# WKUP_I2C0_CFG register map
Vendor: Texas Instruments
Peripheral module from a debugger description file (folder J722S).
Registers are 32-bit, read-write, reset 0x0 unless marked. A register's access mark holds for its fields unless they carry their own. Offsets are as the file gives them; lines under a group give offsets from that group; [hi:lo] are bit positions; {n}, {i} and the like mark numbered series; 'fields as' and 'values as' point back to an identical list; <NAME> marks a mode.

## WKUP_I2C0_CFG
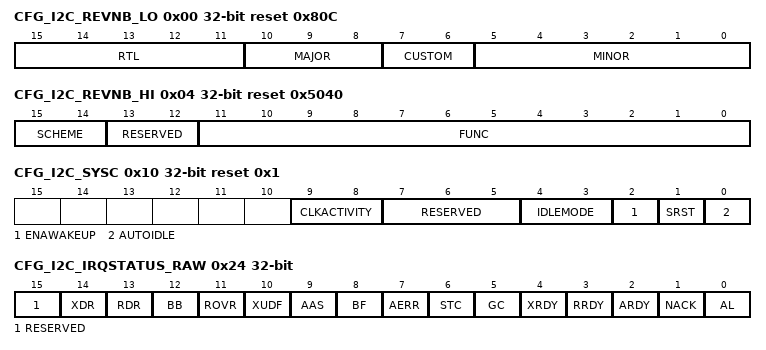
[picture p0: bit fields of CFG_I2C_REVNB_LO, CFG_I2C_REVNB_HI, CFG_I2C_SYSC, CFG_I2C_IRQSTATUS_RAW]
0x00 CFG_I2C_REVNB_LO ro reset 0x80C — Revision Number register (Low)
  [15:11] RTL — RTL version This field changes on bug fix, and resets to
  [10:8] MAJOR — Major Revision This field changes when there is a major feature change This field does not change due to bug fix, or minor feature change
  [7:6] CUSTOM — Indicates a special version for a particular device Consequence of use may avoid use of standard Chip Support Library [CSL] / Drivers 0 if non-custom
  [5:0] MINOR — Minor Revision This field changes when features are scaled up or down This field does not change due to bug fix, or major feature change
0x04 CFG_I2C_REVNB_HI ro reset 0x5040 — Revision Number register (High)
  [15:14] SCHEME — Used to distinguish between old Scheme and current Spare bit to encode future schemes
  [13:12] RESERVED — Reads return 0x1
  [11:0] FUNC — Function: Indicates a software compatible module family
0x10 CFG_I2C_SYSC access not given reset 0x1 — System Configuration register
  [9:8] CLKACTIVITY rw — Clock Activity selection bits
  [7:5] RESERVED — Reads return 0 (access N/A)
  [4:3] IDLEMODE rw — Idle Mode selection bits
  [2] ENAWAKEUP rw — Enable Wakeup control bit
  [1] SRST rw — SoftReset bit
  [0] AUTOIDLE rw — Autoidle bit
0x20 CFG_I2C_EOI wo — End Of Interrupt number specification
  [0] LINE_NUMBER — Software End Of Interrupt [EOI] control Write number of interrupt output
0x24 CFG_I2C_IRQSTATUS_RAW access not given — Per-event raw interrupt status vector
  [15] RESERVED — Write 0s for future compatibility Read returns 0 (access N/A)
  [14] XDR rw — Transmit draining IRQ status
  [13] RDR rw — Receive draining IRQ status
  [12] BB ro — Bus busy statusWriting into this bit has no effect
  [11] ROVR rw — Receive overrun statusWriting into this bit has no effect
  [10] XUDF rw — Transmit underflow statusWriting into this bit has no effect
  [9] AAS rw — Address recognized as target IRQ status
  [8] BF rw — Bus Free IRQ status
  [7] AERR rw — Access Error IRQ status
  [6] STC rw — Start Condition IRQ status
  [5] GC — General call IRQ status Set to '1' by core when General call address detected and interrupt signaled to MPUSS Write '1' to clear (access R/W1C)
  [4] XRDY — Transmit data ready IRQ status Set to '1' by core when transmitter and when new data is requested When set to '1' by core, an interrupt is signaled to MPUSS Write '1' to clear (access R/W1C)
  [3] RRDY — Receive data ready IRQ status Set to '1' by core when receiver mode, a new data is able to be read When set to '1' by core, an interrupt is signaled to MPUSS Write '1' to clear (access R/W1C)
  [2] ARDY — Register access ready IRQ status When set to '1' it indicates that previous access has been performed and registers are ready to be accessed again An interrupt is signaled to MPUSS Write '1' to clear (access R/W1C)
  [1] NACK — No acknowledgement IRQ status Bit is set when No Acknowledge has been received, an interrupt is signaled to MPUSS Write '1' to clear this bit (access R/W1C)
  [0] AL rw — Arbitration lost IRQ status This bit is automatically set by the hardware when it loses the Arbitration in controller transmit mode, an interrupt is signaled to MPUSS During reads, it always returns 0
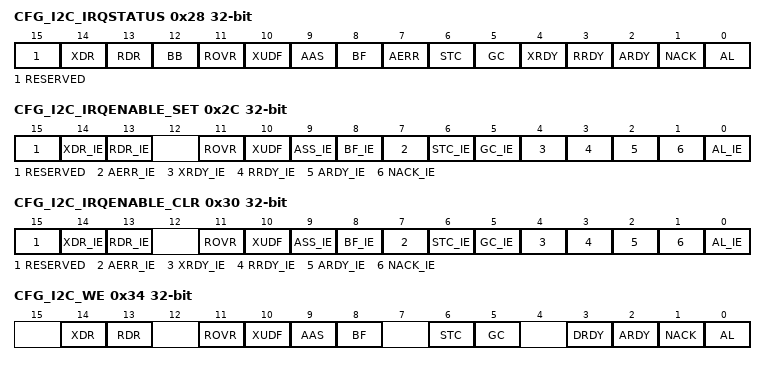
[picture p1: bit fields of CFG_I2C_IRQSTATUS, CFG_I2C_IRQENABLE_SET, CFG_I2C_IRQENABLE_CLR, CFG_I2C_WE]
0x28 CFG_I2C_IRQSTATUS access not given — Per-event enabled interrupt status vector
  [15] RESERVED — Write 0s for future compatibility Read returns 0 (access N/A)
  [14] XDR rw — Transmit draining IRQ enabled status
  [13] RDR rw — Receive draining IRQ enabled status
  [12] BB ro — Bus busy enabled statusWriting into this bit has no effect
  [11] ROVR rw — Receive overrun enabled statusWriting into this bit has no effect
  [10] XUDF rw — Transmit underflow enabled statusWriting into this bit has no effect
  [9] AAS rw — Address recognized as target IRQ enabled status
  [8] BF rw — Bus Free IRQ enabled status
  [7] AERR rw — Access Error IRQ enabled status
  [6] STC rw — Start Condition IRQ enabled status
  [5] GC rw — General call IRQ enabled status Set to '1' by core when General call address detected and interrupt signaled to MPUSS Write '1' to clear
  [4] XRDY rw — Transmit data ready IRQ enabled status Set to '1' by core when transmitter and when new data is requested When set to '1' by core, an interrupt is signaled to MPUSS Write '1' to clear
  [3] RRDY rw — Receive data ready IRQ enabled status Set to '1' by core when receiver mode, a new data is able to be read When set to '1' by core, an interrupt is signaled to MPUSS Write '1' to clear
  [2] ARDY rw — Register access ready IRQ enabled status When set to '1' it indicates that previous access has been performed and registers are ready to be accessed again An interrupt is signaled to MPUSS Write '1' to clear
  [1] NACK rw — No acknowledgement IRQ enabled status Bit is set when No Acknowledge has been received, an interrupt is signaled to MPUSS Write '1' to clear this bit
  [0] AL rw — Arbitration lost IRQ enabled status This bit is automatically set by the hardware when it loses the Arbitration in controller transmit mode, an interrupt is signaled to MPUSS During reads, it always returns 0
0x2C CFG_I2C_IRQENABLE_SET access not given — Per-event interrupt enable bit vector.
  [15] RESERVED — Write 0s for future compatibility Read returns 0 (access N/A)
  [14] XDR_IE rw — Transmit Draining interrupt enable set Mask or unmask the interrupt signaled by bit in I2C_STAT[XDR]
  [13] RDR_IE rw — Receive Draining interrupt enable set Mask or unmask the interrupt signaled by bit in I2C_STAT[RDR]
  [11] ROVR rw — Receive overrun enable set
  [10] XUDF rw — Transmit underflow enable set
  [9] ASS_IE rw — Addressed as Target interrupt enable set Mask or unmask the interrupt signaled by bit in I2C_STAT[AAS]
  [8] BF_IE rw — Bus Free interrupt enable set Mask or unmask the interrupt signaled by bit in I2C_STAT[BF]
  [7] AERR_IE rw — Access Error interrupt enable set Mask or unmask the interrupt signaled by bit in I2C_STAT[AERR]
  [6] STC_IE rw — Start Condition interrupt enable set Mask or unmask the interrupt signaled by bit in I2C_STAT[STC]
  [5] GC_IE rw — General call Interrupt enable set Mask or unmask the interrupt signaled by bit in I2C_STAT[GC]
  [4] XRDY_IE rw — Transmit data ready interrupt enable set Mask or unmask the interrupt signaled by bit in I2C_STAT[XRDY]
  [3] RRDY_IE rw — Receive data ready interrupt enable set Mask or unmask the interrupt signaled by bit in I2C_STAT[RRDY]
  [2] ARDY_IE rw — Register access ready interrupt enable set Mask or unmask the interrupt signaled by bit in I2C_STAT[ARDY]
  [1] NACK_IE rw — No acknowledgement interrupt enable set Mask or unmask the interrupt signaled by bit in I2C_STAT[NACK]
  [0] AL_IE rw — Arbitration lost interrupt enable set Mask or unmask the interrupt signaled by bit in I2C_STAT[AL]
0x30 CFG_I2C_IRQENABLE_CLR access not given — Per-event interrupt clear bit vector.
  [15] RESERVED — Write 0s for future compatibility Read returns 0 (access N/A)
  [14] XDR_IE rw — Transmit Draining interrupt enable clear Mask or unmask the interrupt signaled by bit in I2C_STAT[XDR]
  [13] RDR_IE rw — Receive Draining interrupt enable clear Mask or unmask the interrupt signaled by bit in I2C_STAT[RDR]
  [11] ROVR rw — Receive overrun enable clear
  [10] XUDF rw — Transmit underflow enable clear
  [9] ASS_IE rw — Addressed as Target interrupt enable clear Mask or unmask the interrupt signaled by bit in I2C_STAT[AAS]
  [8] BF_IE rw — Bus Free interrupt enable clear Mask or unmask the interrupt signaled by bit in I2C_STAT[BF]
  [7] AERR_IE rw — Access Error interrupt enable clear Mask or unmask the interrupt signaled by bit in I2C_STAT[AERR]
  [6] STC_IE rw — Start Condition interrupt enable clear Mask or unmask the interrupt signaled by bit in I2C_STAT[STC]
  [5] GC_IE rw — General call Interrupt enable clear Mask or unmask the interrupt signaled by bit in I2C_STAT[GC]
  [4] XRDY_IE rw — Transmit data ready interrupt enable clear Mask or unmask the interrupt signaled by bit in I2C_STAT[XRDY]
  [3] RRDY_IE rw — Receive data ready interrupt enable clear Mask or unmask the interrupt signaled by bit in I2C_STAT[RRDY]
  [2] ARDY_IE rw — Register access ready interrupt enable clear Mask or unmask the interrupt signaled by bit in I2C_STAT[ARDY]
  [1] NACK_IE rw — No acknowledgement interrupt enable clear Mask or unmask the interrupt signaled by bit in I2C_STAT[NACK]
  [0] AL_IE rw — Arbitration lost interrupt enable clear Mask or unmask the interrupt signaled by bit in I2C_STAT[AL]
0x34 CFG_I2C_WE — I2C wakeup enable vector (legacy).
  [14] XDR — Transmit Draining wakeup set
  [13] RDR — Receive Draining wakeup set
  [11] ROVR — Receive overrun wakeup set
  [10] XUDF — Transmit underflow wakeup set
  [9] AAS — Address as target IRQ wakeup set
  [8] BF — Bus Free IRQ wakeup set
  [6] STC — Start Condition IRQ wakeup set
  [5] GC — General call IRQ wakeup set
  [3] DRDY — Receive/Transmit data ready IRQ wakeup set
  [2] ARDY — Register access ready IRQ wakeup set
  [1] NACK — No acknowledgment IRQ wakeup set
  [0] AL — Arbitration lost IRQ wakeup set
0x38 CFG_I2C_DMARXENABLE_SET — Per-event DMA RX enable set.
  [0] DMARX_ENABLE_SET — Receive DMA channel enable set
0x3C CFG_I2C_DMATXENABLE_SET — Per-event DMA TX enable set.
  [0] DMATX_ENABLE_SET — Transmit DMA channel enable set
0x40 CFG_I2C_DMARXENABLE_CLR access not given — Per-event DMA RX enable clear.
  [0] DMARX_ENABLE_CLEAR — Receive DMA channel enable clear (access R/W1C)
0x44 CFG_I2C_DMATXENABLE_CLR access not given — Per-event DMA TX enable clear.
  [0] DMATX_ENABLE_CLEAR — Transmit DMA channel enable clear (access R/W1C)
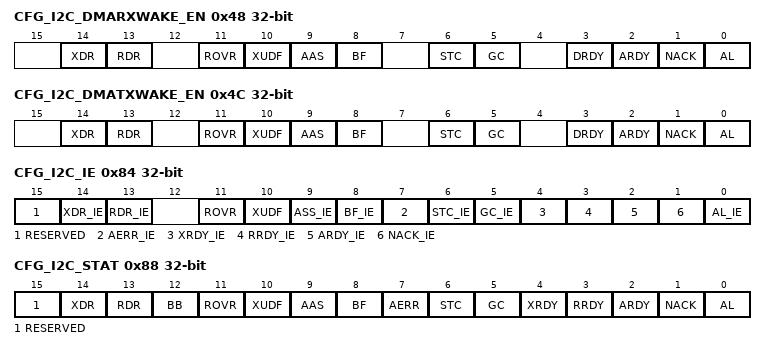
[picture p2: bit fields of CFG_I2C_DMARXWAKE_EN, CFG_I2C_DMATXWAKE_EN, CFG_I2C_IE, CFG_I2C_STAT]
0x48 CFG_I2C_DMARXWAKE_EN — Per-event DMA RX wakeup enable.
  fields as CFG_I2C_WE
0x4C CFG_I2C_DMATXWAKE_EN — Per-event DMA TX wakeup enable.
  fields as CFG_I2C_WE
0x84 CFG_I2C_IE access not given — I2C interrupt enable vector (legacy).
  [15] RESERVED — Write 0s for future compatibility Read returns 0 (access N/A)
  [14] XDR_IE rw — Transmit Draining interrupt enable Mask or unmask the interrupt signaled by bit in I2C_STAT[XDR]
  [13] RDR_IE rw — Receive Draining interrupt enable Mask or unmask the interrupt signaled by bit in I2C_STAT[RDR]
  [11] ROVR rw — Receive overrun enable set
  [10] XUDF rw — Transmit underflow enable set
  [9] ASS_IE rw — Addressed as Target interrupt enable Mask or unmask the interrupt signaled by bit in I2C_STAT[AAS]
  [8] BF_IE rw — Bus Free interrupt enable Mask or unmask the interrupt signaled by bit in I2C_STAT[BF]
  [7] AERR_IE rw — Access Error interrupt enable Mask or unmask the interrupt signaled by bit in I2C_STAT[AERR]
  [6] STC_IE rw — Start Condition interrupt enable Mask or unmask the interrupt signaled by bit in I2C_STAT[STC]
  [5] GC_IE rw — General call Interrupt enable Mask or unmask the interrupt signaled by bit in I2C_STAT[GC]
  [4] XRDY_IE rw — Transmit data ready interrupt enable Mask or unmask the interrupt signaled by bit in I2C_STAT[XRDY]
  [3] RRDY_IE rw — Receive data ready interrupt enable Mask or unmask the interrupt signaled by bit in I2C_STAT[RRDY]
  [2] ARDY_IE rw — Register access ready interrupt enable Mask or unmask the interrupt signaled by bit in I2C_STAT[ARDY]
  [1] NACK_IE rw — No acknowledgement interrupt enable Mask or unmask the interrupt signaled by bit in I2C_STAT[NACK]
  [0] AL_IE rw — Arbitration lost interrupt enable Mask or unmask the interrupt signaled by bit in I2C_STAT[AL]
0x88 CFG_I2C_STAT access not given — I2C interrupt status vector (legacy).
  [15] RESERVED — Write 0s for future compatibility Read returns 0 (access N/A)
  [14] XDR rw — Transmit draining IRQ status
  [13] RDR rw — Receive draining IRQ status
  [12] BB ro — Bus busy statusWriting into this bit has no effect
  [11] ROVR rw — Receive overrun statusWriting into this bit has no effect
  [10] XUDF rw — Transmit underflow statusWriting into this bit has no effect
  [9] AAS rw — Address recognized as target IRQ status
  [8] BF rw — Bus Free IRQ status
  [7] AERR rw — Access Error IRQ status
  [6] STC rw — Start Condition IRQ status
  [5] GC rw — General call IRQ status Set to '1' by core when General call address detected and interrupt signaled to MPUSS Write '1' to clear
  [4] XRDY rw — Transmit data ready IRQ status Set to '1' by core when transmitter and when new data is requested When set to '1' by core, an interrupt is signaled to MPUSS Write '1' to clear
  [3] RRDY rw — Receive data ready IRQ status Set to '1' by core when receiver mode, a new data is able to be read When set to '1' by core, an interrupt is signaled to MPUSS Write '1' to clear
  [2] ARDY rw — Register access ready IRQ status When set to '1' it indicates that previous access has been performed and registers are ready to be accessed again An interrupt is signaled to MPUSS Write '1' to clear
  [1] NACK rw — No acknowledgement IRQ status Bit is set when No Acknowledge has been received, an interrupt is signaled to MPUSS Write '1' to clear this bit
  [0] AL rw — Arbitration lost IRQ status This bit is automatically set by the hardware when it loses the Arbitration in controller transmit mode, an interrupt is signaled to MPUSS During reads, it always returns 0
0x90 CFG_I2C_SYSS ro — System Status register
  [0] RDONE — Reset done bit
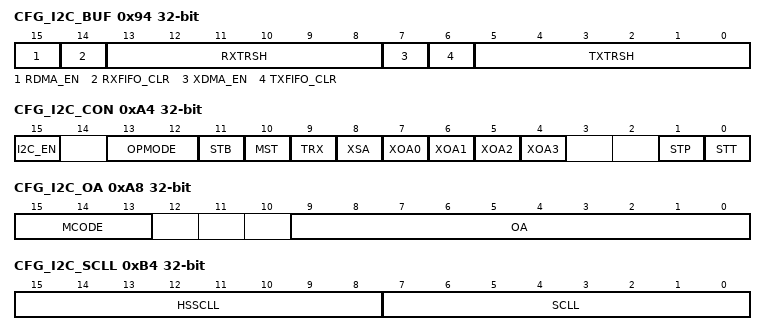
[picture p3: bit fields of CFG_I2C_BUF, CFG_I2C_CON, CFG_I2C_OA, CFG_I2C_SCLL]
0x94 CFG_I2C_BUF — Buffer Configuration register
  [15] RDMA_EN — Receive DMA channel enable
  [14] RXFIFO_CLR — Receive FIFO clear
  [13:8] RXTRSH — Threshold value for FIFO buffer in RX mode
  [7] XDMA_EN — Transmit DMA channel enable
  [6] TXFIFO_CLR — Transmit FIFO clear
  [5:0] TXTRSH — Threshold value for FIFO buffer in TX mode
0x98 CFG_I2C_CNT — Data counter register
  [15:0] DCOUNT — Data count
0x9C CFG_I2C_DATA — Data access register
  [7:0] DATA — Transmit/Receive data FIFO endpoint
0xA4 CFG_I2C_CON — I2C configuration register.
  [15] I2C_EN — I2C module enable
  [13:12] OPMODE — Operation mode selection
  [11] STB — Start byte mode [controller mode only]
  [10] MST — Controller/target mode
  [9] TRX — Transmitter/Receiver mode [controller mode only]
  [8] XSA — Expand Target address
  [7-n] XOA{n} (n=0..3) — Expand Own address {n}
  [1] STP — Stop condition [controller mode only]
  [0] STT — Start condition [controller mode only]
0xA8 CFG_I2C_OA — Own address register
  [15:13] MCODE — Controller Code
  [9:0] OA — Own address
0xAC CFG_I2C_SA reset 0x3FF — Target address register
  [9:0] SA — Target address
0xB0 CFG_I2C_PSC — I2C Clock Prescaler Register
  [7:0] PSC — Fast/Standard mode prescale sampling clock divider value 0x0: Divide by 1 0x1: Divide by 2 0xFF: Divide by 256
0xB4 CFG_I2C_SCLL — I2C SCL Low Time Register.
  [15:8] HSSCLL — High Speed mode SCL low time
  [7:0] SCLL — Fast/Standard mode SCL low time
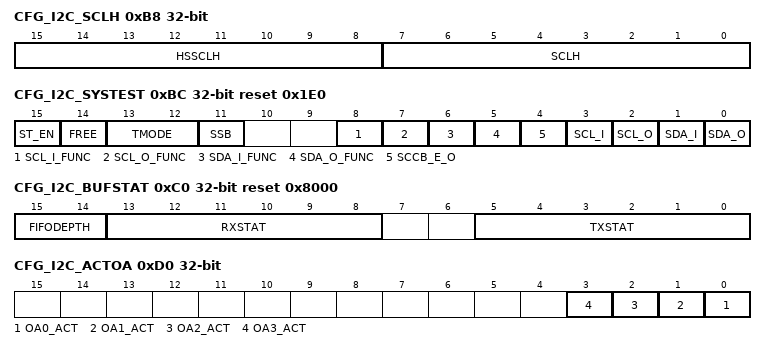
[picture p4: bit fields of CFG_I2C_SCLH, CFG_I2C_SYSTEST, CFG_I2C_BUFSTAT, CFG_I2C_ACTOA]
0xB8 CFG_I2C_SCLH — I2C SCL High Time Register.
  [15:8] HSSCLH — High Speed mode SCL high time
  [7:0] SCLH — Fast/Standard mode SCL high time
0xBC CFG_I2C_SYSTEST access per field reset 0x1E0 — I2C System Test Register.
  [15] ST_EN rw — System test enable
  [14] FREE rw — Free running mode [on breakpoint]
  [13:12] TMODE rw — Test mode select
  [11] SSB rw — Set status bits
  [8] SCL_I_FUNC ro — SCL line input value [functional mode]
  [7] SCL_O_FUNC ro — SCL line output value [functional mode]
  [6] SDA_I_FUNC ro — SDA line input value [functional mode]
  [5] SDA_O_FUNC ro — SDA line output value [functional mode]
  [4] SCCB_E_O rw — SCCB_E line sense output value
  [3] SCL_I ro — SCL line sense input value
  [2] SCL_O rw — SCL line drive output value
  [1] SDA_I ro — SDA line sense input value
  [0] SDA_O rw — SDA line drive output value
0xC0 CFG_I2C_BUFSTAT ro reset 0x8000 — I2C Buffer Status Register.
  [15:14] FIFODEPTH — Internal FIFO buffers depth
  [13:8] RXSTAT — RX Buffer Status
  [5:0] TXSTAT — TX Buffer Status
{0xC0+4i} CFG_I2C_OA{i} (i=1..3) — I2C Own Address {i} Register
  [9:0] OA{i} — Own address {i}
0xD0 CFG_I2C_ACTOA ro — I2C Active Own Address Register.
  [n] OA{n}_ACT (n=0..3) — Own Address {n} active
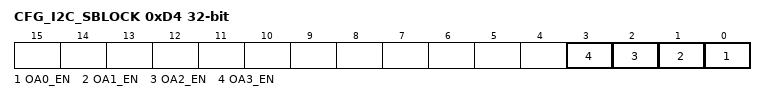
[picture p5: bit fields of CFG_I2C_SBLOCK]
0xD4 CFG_I2C_SBLOCK — I2C Clock Blocking Enable Register.
  [n] OA{n}_EN (n=0..3) — Enable I2C Clock Blocking for Own Address {n}
